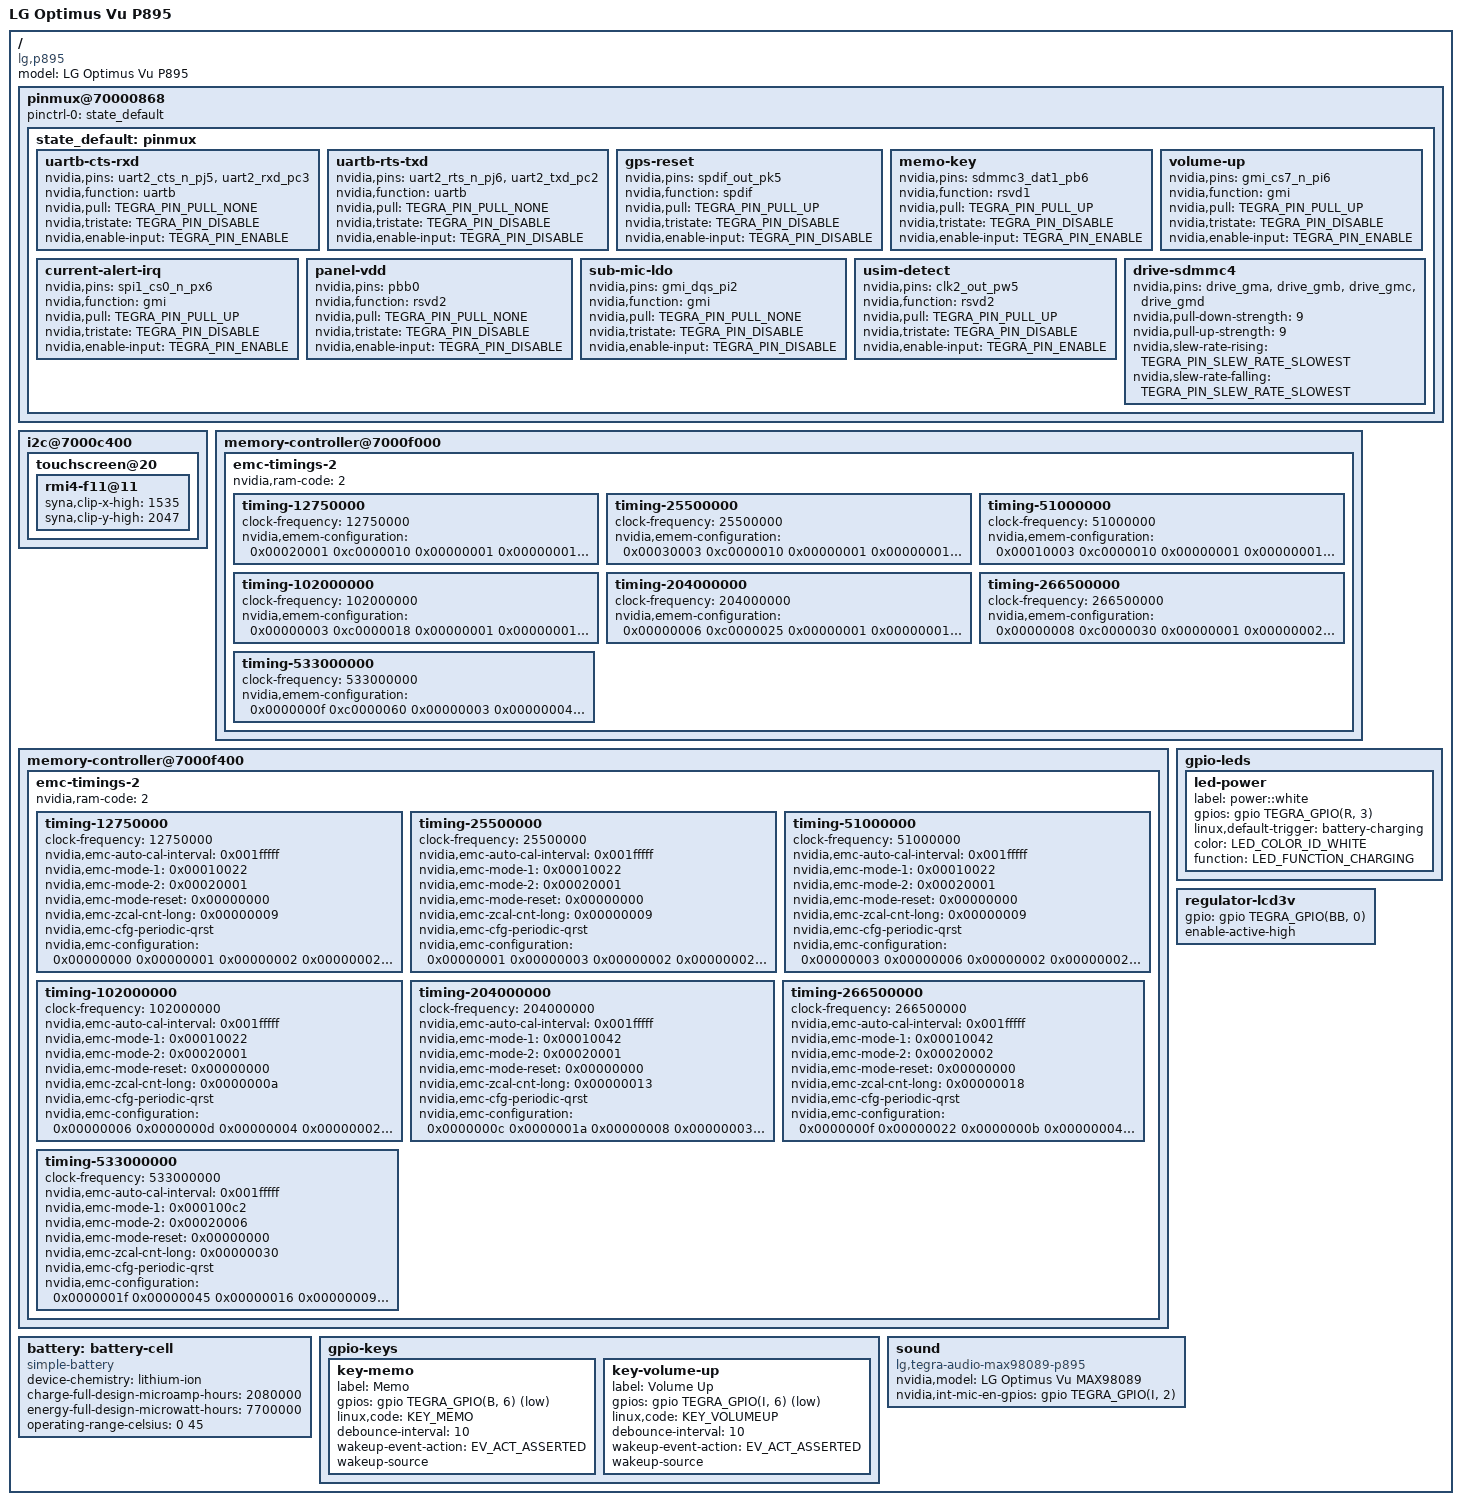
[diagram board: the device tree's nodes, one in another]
// SPDX-License-Identifier: GPL-2.0
/dts-v1/;

#include "tegra30-lg-x3.dtsi"

/ {
	model = "LG Optimus Vu P895";
	compatible = "lg,p895", "nvidia,tegra30";

	pinmux@70000868 {
		pinctrl-names = "default";
		pinctrl-0 = <&state_default>;

		state_default: pinmux {
			/* GNSS UART-B pinmux */
			uartb-cts-rxd {
				nvidia,pins = "uart2_cts_n_pj5",
						"uart2_rxd_pc3";
				nvidia,function = "uartb";
				nvidia,pull = <TEGRA_PIN_PULL_NONE>;
				nvidia,tristate = <TEGRA_PIN_DISABLE>;
				nvidia,enable-input = <TEGRA_PIN_ENABLE>;
			};
			uartb-rts-txd {
				nvidia,pins = "uart2_rts_n_pj6",
						"uart2_txd_pc2";
				nvidia,function = "uartb";
				nvidia,pull = <TEGRA_PIN_PULL_NONE>;
				nvidia,tristate = <TEGRA_PIN_DISABLE>;
				nvidia,enable-input = <TEGRA_PIN_DISABLE>;
			};
			gps-reset {
				nvidia,pins = "spdif_out_pk5";
				nvidia,function = "spdif";
				nvidia,pull = <TEGRA_PIN_PULL_UP>;
				nvidia,tristate = <TEGRA_PIN_DISABLE>;
				nvidia,enable-input = <TEGRA_PIN_DISABLE>;
			};

			/* GPIO keys pinmux */
			memo-key {
				nvidia,pins = "sdmmc3_dat1_pb6";
				nvidia,function = "rsvd1";
				nvidia,pull = <TEGRA_PIN_PULL_UP>;
				nvidia,tristate = <TEGRA_PIN_DISABLE>;
				nvidia,enable-input = <TEGRA_PIN_ENABLE>;
			};
			volume-up {
				nvidia,pins = "gmi_cs7_n_pi6";
				nvidia,function = "gmi";
				nvidia,pull = <TEGRA_PIN_PULL_UP>;
				nvidia,tristate = <TEGRA_PIN_DISABLE>;
				nvidia,enable-input = <TEGRA_PIN_ENABLE>;
			};

			/* Sensors pinmux */
			current-alert-irq {
				nvidia,pins = "spi1_cs0_n_px6";
				nvidia,function = "gmi";
				nvidia,pull = <TEGRA_PIN_PULL_UP>;
				nvidia,tristate = <TEGRA_PIN_DISABLE>;
				nvidia,enable-input = <TEGRA_PIN_ENABLE>;
			};

			/* Panel pinmux */
			panel-vdd {
				nvidia,pins = "pbb0";
				nvidia,function = "rsvd2";
				nvidia,pull = <TEGRA_PIN_PULL_NONE>;
				nvidia,tristate = <TEGRA_PIN_DISABLE>;
				nvidia,enable-input = <TEGRA_PIN_DISABLE>;
			};

			/* AUDIO pinmux */
			sub-mic-ldo {
				nvidia,pins = "gmi_dqs_pi2";
				nvidia,function = "gmi";
				nvidia,pull = <TEGRA_PIN_PULL_NONE>;
				nvidia,tristate = <TEGRA_PIN_DISABLE>;
				nvidia,enable-input = <TEGRA_PIN_DISABLE>;
			};

			/* Modem pinmux */
			usim-detect {
				nvidia,pins = "clk2_out_pw5";
				nvidia,function = "rsvd2";
				nvidia,pull = <TEGRA_PIN_PULL_UP>;
				nvidia,tristate = <TEGRA_PIN_DISABLE>;
				nvidia,enable-input = <TEGRA_PIN_ENABLE>;
			};

			/* GPIO power/drive control */
			drive-sdmmc4 {
				nvidia,pins = "drive_gma",
						"drive_gmb",
						"drive_gmc",
						"drive_gmd";
				nvidia,pull-down-strength = <9>;
				nvidia,pull-up-strength = <9>;
				nvidia,slew-rate-rising = <TEGRA_PIN_SLEW_RATE_SLOWEST>;
				nvidia,slew-rate-falling = <TEGRA_PIN_SLEW_RATE_SLOWEST>;
			};
		};
	};

	i2c@7000c400 {
		touchscreen@20 {
			rmi4-f11@11 {
				syna,clip-x-high = <1535>;
				syna,clip-y-high = <2047>;
			};
		};
	};

	memory-controller@7000f000 {
		emc-timings-2 {
			/* Hynix 1GB H9TCNNN8JDMMPR LPDDR2 533MHz */
			nvidia,ram-code = <2>;

			timing-12750000 {
				clock-frequency = <12750000>;

				nvidia,emem-configuration = < 0x00020001 0xc0000010
					0x00000001 0x00000001 0x00000002 0x00000000
					0x00000003 0x00000001 0x00000002 0x00000004
					0x00000001 0x00000000 0x00000002 0x00000002
					0x02020001 0x00060402 0x77230303 0x001f0000 >;
			};

			timing-25500000 {
				clock-frequency = <25500000>;

				nvidia,emem-configuration = < 0x00030003 0xc0000010
					0x00000001 0x00000001 0x00000002 0x00000000
					0x00000003 0x00000001 0x00000002 0x00000004
					0x00000001 0x00000000 0x00000002 0x00000002
					0x02020001 0x00060402 0x73e30303 0x001f0000 >;
			};

			timing-51000000 {
				clock-frequency = <51000000>;

				nvidia,emem-configuration = < 0x00010003 0xc0000010
					0x00000001 0x00000001 0x00000002 0x00000000
					0x00000003 0x00000001 0x00000002 0x00000004
					0x00000001 0x00000000 0x00000002 0x00000002
					0x02020001 0x00060402 0x72c30303 0x001f0000 >;
			};

			timing-102000000 {
				clock-frequency = <102000000>;

				nvidia,emem-configuration = < 0x00000003 0xc0000018
					0x00000001 0x00000001 0x00000003 0x00000001
					0x00000003 0x00000001 0x00000002 0x00000004
					0x00000001 0x00000000 0x00000002 0x00000002
					0x02020001 0x00060403 0x72430504 0x001f0000 >;
			};

			timing-204000000 {
				clock-frequency = <204000000>;

				nvidia,emem-configuration = < 0x00000006 0xc0000025
					0x00000001 0x00000001 0x00000006 0x00000003
					0x00000005 0x00000001 0x00000002 0x00000004
					0x00000001 0x00000000 0x00000003 0x00000002
					0x02030001 0x00070506 0x71e40a07 0x001f0000 >;
			};

			timing-266500000 {
				clock-frequency = <266500000>;

				nvidia,emem-configuration = < 0x00000008 0xc0000030
					0x00000001 0x00000002 0x00000008 0x00000004
					0x00000006 0x00000001 0x00000002 0x00000005
					0x00000001 0x00000000 0x00000003 0x00000003
					0x03030001 0x00090608 0x70040c09 0x001f0000 >;
			};

			timing-533000000 {
				clock-frequency = <533000000>;

				nvidia,emem-configuration = < 0x0000000f 0xc0000060
					0x00000003 0x00000004 0x00000010 0x0000000a
					0x0000000d 0x00000002 0x00000002 0x00000008
					0x00000002 0x00000000 0x00000004 0x00000005
					0x05040002 0x00110b10 0x70281811 0x001f0000 >;
			};
		};
	};

	memory-controller@7000f400 {
		emc-timings-2 {
			/* Hynix 1GB H9TCNNN8JDMMPR LPDDR2 533MHz */
			nvidia,ram-code = <2>;

			timing-12750000 {
				clock-frequency = <12750000>;

				nvidia,emc-auto-cal-interval = <0x001fffff>;
				nvidia,emc-mode-1 = <0x00010022>;
				nvidia,emc-mode-2 = <0x00020001>;
				nvidia,emc-mode-reset = <0x00000000>;
				nvidia,emc-zcal-cnt-long = <0x00000009>;
				nvidia,emc-cfg-periodic-qrst;

				nvidia,emc-configuration =  < 0x00000000
					0x00000001 0x00000002 0x00000002 0x00000004
					0x00000004 0x00000001 0x00000005 0x00000002
					0x00000002 0x00000001 0x00000001 0x00000000
					0x00000001 0x00000003 0x00000001 0x0000000b
					0x00000009 0x0000002f 0x00000000 0x0000000b
					0x00000001 0x00000001 0x00000002 0x00000000
					0x00000001 0x00000007 0x00000002 0x00000002
					0x00000003 0x00000008 0x00000004 0x00000004
					0x00000002 0x00000036 0x00000004 0x00000004
					0x00000000 0x00000000 0x00004282 0x007800a4
					0x00008000 0x000fc000 0x000fc000 0x000fc000
					0x000fc000 0x000fc000 0x000fc000 0x000fc000
					0x000fc000 0x00000000 0x00000000 0x00000000
					0x00000000 0x00000000 0x00000000 0x00000000
					0x00000000 0x00000000 0x00000000 0x00000000
					0x00000000 0x00000000 0x00000000 0x00000000
					0x00000000 0x000fc000 0x000fc000 0x000fc000
					0x000fc000 0x00100220 0x0800201c 0x00000000
					0x77ffc004 0x01f1f008 0x00000000 0x00000007
					0x08000068 0x08000000 0x00000802 0x00064000
					0x00000009 0x00090009 0xa0f10000 0x00000000
					0x00000000 0x80000164 0xe0000000 0xff00ff00 >;
			};

			timing-25500000 {
				clock-frequency = <25500000>;

				nvidia,emc-auto-cal-interval = <0x001fffff>;
				nvidia,emc-mode-1 = <0x00010022>;
				nvidia,emc-mode-2 = <0x00020001>;
				nvidia,emc-mode-reset = <0x00000000>;
				nvidia,emc-zcal-cnt-long = <0x00000009>;
				nvidia,emc-cfg-periodic-qrst;

				nvidia,emc-configuration =  < 0x00000001
					0x00000003 0x00000002 0x00000002 0x00000004
					0x00000004 0x00000001 0x00000005 0x00000002
					0x00000002 0x00000001 0x00000001 0x00000000
					0x00000001 0x00000003 0x00000001 0x0000000b
					0x00000009 0x00000060 0x00000000 0x00000018
					0x00000001 0x00000001 0x00000002 0x00000000
					0x00000001 0x00000007 0x00000004 0x00000004
					0x00000003 0x00000008 0x00000004 0x00000004
					0x00000002 0x0000006b 0x00000004 0x00000004
					0x00000000 0x00000000 0x00004282 0x007800a4
					0x00008000 0x000fc000 0x000fc000 0x000fc000
					0x000fc000 0x000fc000 0x000fc000 0x000fc000
					0x000fc000 0x00000000 0x00000000 0x00000000
					0x00000000 0x00000000 0x00000000 0x00000000
					0x00000000 0x00000000 0x00000000 0x00000000
					0x00000000 0x00000000 0x00000000 0x00000000
					0x00000000 0x000fc000 0x000fc000 0x000fc000
					0x000fc000 0x00100220 0x0800201c 0x00000000
					0x77ffc004 0x01f1f008 0x00000000 0x00000007
					0x08000068 0x08000000 0x00000802 0x00064000
					0x0000000a 0x00090009 0xa0f10000 0x00000000
					0x00000000 0x800001c5 0xd0000000 0xff00ff00 >;
			};

			timing-51000000 {
				clock-frequency = <51000000>;

				nvidia,emc-auto-cal-interval = <0x001fffff>;
				nvidia,emc-mode-1 = <0x00010022>;
				nvidia,emc-mode-2 = <0x00020001>;
				nvidia,emc-mode-reset = <0x00000000>;
				nvidia,emc-zcal-cnt-long = <0x00000009>;
				nvidia,emc-cfg-periodic-qrst;

				nvidia,emc-configuration =  < 0x00000003
					0x00000006 0x00000002 0x00000002 0x00000004
					0x00000004 0x00000001 0x00000005 0x00000002
					0x00000002 0x00000001 0x00000001 0x00000000
					0x00000001 0x00000003 0x00000001 0x0000000b
					0x00000009 0x000000c0 0x00000000 0x00000030
					0x00000001 0x00000001 0x00000002 0x00000000
					0x00000001 0x00000007 0x00000008 0x00000008
					0x00000003 0x00000008 0x00000004 0x00000004
					0x00000002 0x000000d5 0x00000004 0x00000004
					0x00000000 0x00000000 0x00004282 0x007800a4
					0x00008000 0x000fc000 0x000fc000 0x000fc000
					0x000fc000 0x000fc000 0x000fc000 0x000fc000
					0x000fc000 0x00000000 0x00000000 0x00000000
					0x00000000 0x00000000 0x00000000 0x00000000
					0x00000000 0x00000000 0x00000000 0x00000000
					0x00000000 0x00000000 0x00000000 0x00000000
					0x00000000 0x000fc000 0x000fc000 0x000fc000
					0x000fc000 0x00100220 0x0800201c 0x00000000
					0x77ffc004 0x01f1f008 0x00000000 0x00000007
					0x08000068 0x08000000 0x00000802 0x00064000
					0x00000013 0x00090009 0xa0f10000 0x00000000
					0x00000000 0x80000287 0xd0000000 0xff00ff00 >;
			};

			timing-102000000 {
				clock-frequency = <102000000>;

				nvidia,emc-auto-cal-interval = <0x001fffff>;
				nvidia,emc-mode-1 = <0x00010022>;
				nvidia,emc-mode-2 = <0x00020001>;
				nvidia,emc-mode-reset = <0x00000000>;
				nvidia,emc-zcal-cnt-long = <0x0000000a>;
				nvidia,emc-cfg-periodic-qrst;

				nvidia,emc-configuration =  < 0x00000006
					0x0000000d 0x00000004 0x00000002 0x00000004
					0x00000004 0x00000001 0x00000005 0x00000002
					0x00000002 0x00000001 0x00000001 0x00000000
					0x00000001 0x00000003 0x00000001 0x0000000b
					0x00000009 0x00000181 0x00000000 0x00000060
					0x00000001 0x00000001 0x00000002 0x00000000
					0x00000001 0x00000007 0x0000000f 0x0000000f
					0x00000003 0x00000008 0x00000004 0x00000004
					0x00000002 0x000001a9 0x00000004 0x00000006
					0x00000000 0x00000000 0x00004282 0x007800a4
					0x00008000 0x000fc000 0x000fc000 0x000fc000
					0x000fc000 0x000fc000 0x000fc000 0x000fc000
					0x000fc000 0x00000000 0x00000000 0x00000000
					0x00000000 0x00000000 0x00000000 0x00000000
					0x00000000 0x00000000 0x00000000 0x00000000
					0x00000000 0x00000000 0x00000000 0x00000000
					0x00000000 0x000fc000 0x000fc000 0x000fc000
					0x000fc000 0x00100220 0x0800201c 0x00000000
					0x77ffc004 0x01f1f008 0x00000000 0x00000007
					0x08000068 0x08000000 0x00000802 0x00064000
					0x00000025 0x00090009 0xa0f10000 0x00000000
					0x00000000 0x8000040b 0xd0000000 0xff00ff00 >;
			};

			timing-204000000 {
				clock-frequency = <204000000>;

				nvidia,emc-auto-cal-interval = <0x001fffff>;
				nvidia,emc-mode-1 = <0x00010042>;
				nvidia,emc-mode-2 = <0x00020001>;
				nvidia,emc-mode-reset = <0x00000000>;
				nvidia,emc-zcal-cnt-long = <0x00000013>;
				nvidia,emc-cfg-periodic-qrst;

				nvidia,emc-configuration =  < 0x0000000c
					0x0000001a 0x00000008 0x00000003 0x00000005
					0x00000004 0x00000001 0x00000006 0x00000003
					0x00000003 0x00000002 0x00000002 0x00000000
					0x00000001 0x00000004 0x00000001 0x0000000c
					0x0000000a 0x00000303 0x00000000 0x000000c0
					0x00000001 0x00000001 0x00000003 0x00000000
					0x00000001 0x00000007 0x0000001d 0x0000001d
					0x00000004 0x0000000b 0x00000005 0x00000004
					0x00000002 0x00000351 0x00000005 0x00000004
					0x00000000 0x00000000 0x00004282 0x004400a4
					0x00008000 0x00080000 0x00080000 0x00080000
					0x00080000 0x00072000 0x00072000 0x00072000
					0x00072000 0x00000000 0x00000000 0x00000000
					0x00000000 0x00000000 0x00000000 0x00000000
					0x00000000 0x00000000 0x00000000 0x00000000
					0x00000000 0x00000000 0x00000000 0x00000000
					0x00000000 0x00080000 0x00080000 0x00080000
					0x00080000 0x000e0220 0x0800201c 0x00000000
					0x77ffc004 0x01f1f008 0x00000000 0x00000007
					0x08000068 0x08000000 0x00000802 0x00064000
					0x0000004a 0x00090009 0xa0f10000 0x00000000
					0x00000000 0x80000713 0xe0000000 0xff00ff00 >;
			};

			timing-266500000 {
				clock-frequency = <266500000>;

				nvidia,emc-auto-cal-interval = <0x001fffff>;
				nvidia,emc-mode-1 = <0x00010042>;
				nvidia,emc-mode-2 = <0x00020002>;
				nvidia,emc-mode-reset = <0x00000000>;
				nvidia,emc-zcal-cnt-long = <0x00000018>;
				nvidia,emc-cfg-periodic-qrst;

				nvidia,emc-configuration =  < 0x0000000f
					0x00000022 0x0000000b 0x00000004 0x00000005
					0x00000005 0x00000001 0x00000007 0x00000004
					0x00000004 0x00000002 0x00000002 0x00000000
					0x00000002 0x00000005 0x00000002 0x0000000c
					0x0000000b 0x000003ef 0x00000000 0x000000fb
					0x00000001 0x00000001 0x00000004 0x00000000
					0x00000001 0x00000009 0x00000026 0x00000026
					0x00000004 0x0000000e 0x00000006 0x00000004
					0x00000002 0x00000455 0x00000000 0x00000004
					0x00000000 0x00000000 0x00006282 0x003200a4
					0x00008000 0x00070000 0x00070000 0x00070000
					0x00070000 0x00072000 0x00072000 0x00072000
					0x00072000 0x00000000 0x00000000 0x00000000
					0x00000000 0x00000000 0x00000000 0x00000000
					0x00000000 0x00000000 0x00000000 0x00000000
					0x00000000 0x00000000 0x00000000 0x00000000
					0x00000000 0x00080002 0x00080002 0x00080002
					0x00080002 0x000e0220 0x0800003d 0x00000000
					0x77ffc004 0x01f1f008 0x00000000 0x00000007
					0x08000068 0x08000000 0x00000802 0x00064000
					0x00000060 0x000a000a 0xa0f10000 0x00000000
					0x00000000 0x800008ee 0xe0000000 0xff00ff00 >;
			};

			timing-533000000 {
				clock-frequency = <533000000>;

				nvidia,emc-auto-cal-interval = <0x001fffff>;
				nvidia,emc-mode-1 = <0x000100c2>;
				nvidia,emc-mode-2 = <0x00020006>;
				nvidia,emc-mode-reset = <0x00000000>;
				nvidia,emc-zcal-cnt-long = <0x00000030>;
				nvidia,emc-cfg-periodic-qrst;

				nvidia,emc-configuration =  < 0x0000001f
					0x00000045 0x00000016 0x00000009 0x00000008
					0x00000009 0x00000003 0x0000000d 0x00000009
					0x00000009 0x00000005 0x00000003 0x00000000
					0x00000004 0x0000000a 0x00000006 0x0000000d
					0x00000010 0x000007df 0x00000000 0x000001f7
					0x00000003 0x00000003 0x00000009 0x00000000
					0x00000001 0x0000000f 0x0000004b 0x0000004b
					0x00000008 0x0000001b 0x0000000c 0x00000004
					0x00000002 0x000008aa 0x00000000 0x00000004
					0x00000000 0x00000000 0x00006282 0xf0120091
					0x00008000 0x0000000c 0x0000000c 0x0000000c
					0x0000000c 0x0000000a 0x0000000a 0x0000000a
					0x0000000a 0x00000000 0x00000000 0x00000000
					0x00000000 0x00000000 0x00000000 0x00000000
					0x00000000 0x00000000 0x00000000 0x00000000
					0x00000000 0x00000000 0x00000000 0x00000000
					0x00000000 0x0000000c 0x0000000c 0x0000000c
					0x0000000c 0x000c0220 0x0800003d 0x00000000
					0x77ffc004 0x01f1f408 0x00000000 0x00000007
					0x08000068 0x08000000 0x00000802 0x00064000
					0x000000c0 0x000e000e 0xa0f10000 0x00000000
					0x00000000 0x800010d9 0xe0000000 0xff00ff88 >;
			};
		};
	};

	battery: battery-cell {
		compatible = "simple-battery";
		device-chemistry = "lithium-ion";
		charge-full-design-microamp-hours = <2080000>;
		energy-full-design-microwatt-hours = <7700000>;
		operating-range-celsius = <0 45>;
	};

	gpio-keys {
		key-memo {
			label = "Memo";
			gpios = <&gpio TEGRA_GPIO(B, 6) GPIO_ACTIVE_LOW>;
			linux,code = <KEY_MEMO>;
			debounce-interval = <10>;
			wakeup-event-action = <EV_ACT_ASSERTED>;
			wakeup-source;
		};

		key-volume-up {
			label = "Volume Up";
			gpios = <&gpio TEGRA_GPIO(I, 6) GPIO_ACTIVE_LOW>;
			linux,code = <KEY_VOLUMEUP>;
			debounce-interval = <10>;
			wakeup-event-action = <EV_ACT_ASSERTED>;
			wakeup-source;
		};
	};

	gpio-leds {
		led-power {
			label = "power::white";
			gpios = <&gpio TEGRA_GPIO(R, 3) GPIO_ACTIVE_HIGH>;

			linux,default-trigger = "battery-charging";

			color = <LED_COLOR_ID_WHITE>;
			function = LED_FUNCTION_CHARGING;
		};
	};

	regulator-lcd3v {
		gpio = <&gpio TEGRA_GPIO(BB, 0) GPIO_ACTIVE_HIGH>;
		enable-active-high;
	};

	sound {
		compatible = "lg,tegra-audio-max98089-p895",
			     "nvidia,tegra-audio-max98089";
		nvidia,model = "LG Optimus Vu MAX98089";

		nvidia,int-mic-en-gpios = <&gpio TEGRA_GPIO(I, 2) GPIO_ACTIVE_HIGH>;
	};
};
